VERSION "Yunle_CAN_Integrated_CANdb Release v1.0.2"

NS_ :

BS_:

BU_: ACU ADAS BMS Compressor Diagnostics ECAS EPS HVAC IBC Motor_Control SAS_SW SCU TBOX TPMS UDAN VCU Vector__XXX
VAL_TABLE_ New_Value_Table_49 ;
VAL_TABLE_ VT_OnOff 0 "Off" 1 "On" ;
VAL_TABLE_ VT_Enable 0 "Disable" 1 "Enable" ;
VAL_TABLE_ VT_Validity 0 "Invalid" 1 "Valid" ;
VAL_TABLE_ VT_Active 0 "Inactive" 1 "Active" ;
VAL_TABLE_ VT_Request2 0 "NoRequest" 1 "Request" 2 "Reserved2" 3 "Reserved3" ;
VAL_TABLE_ VT_ShiftLevel 0 "Invalid" 1 "D" 2 "N" 3 "R" ;
VAL_TABLE_ VT_DriveMode 0 "Manual" 1 "Remote" 2 "Auto" 3 "Reserved" ;
VAL_TABLE_ VT_IgnitionState 0 "Off" 1 "Acc" 2 "On" 3 "Start" ;
VAL_TABLE_ VT_Direction 0 "LeftOrNegative" 1 "RightOrPositive" ;
VAL_TABLE_ VT_WarningLevel 0 "Normal" 1 "Warning" 2 "Derating" 3 "Fault" 4 "Severe" 5 "Reserved5" 6 "Reserved6" 7 "Reserved7" ;
VAL_TABLE_ VT_TorqueOrSpeedMode 0 "TorqueMode" 1 "SpeedMode" ;

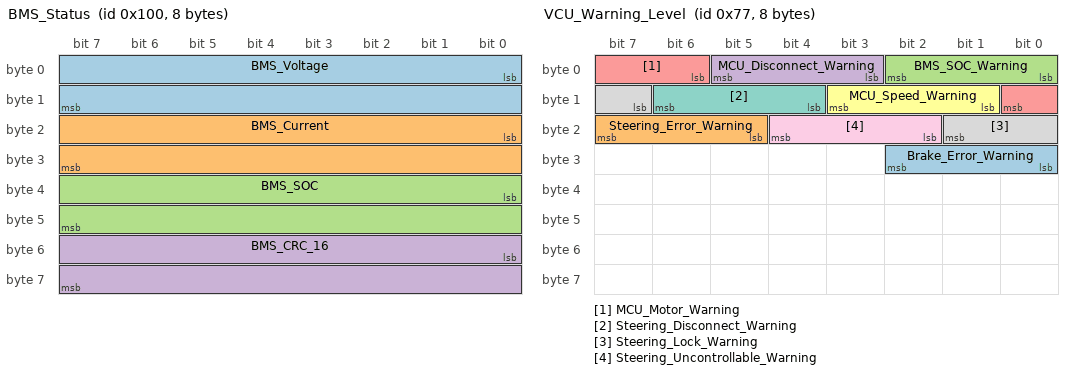
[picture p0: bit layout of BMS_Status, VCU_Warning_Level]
BO_ 256 BMS_Status: 8 BMS
 SG_ BMS_Voltage : 0|16@1+ (0.1,0) [0|100] "V"  VCU,TBOX
 SG_ BMS_Current : 16|16@1- (0.1,0) [-500|500] "A"  VCU,TBOX
 SG_ BMS_SOC : 32|16@1+ (1,0) [0|100] "%"  VCU,TBOX
 SG_ BMS_CRC_16 : 48|16@1+ (1,0) [0|65535] "" Vector__XXX

BO_ 119 VCU_Warning_Level: 8 VCU
 SG_ Brake_Error_Warning : 24|3@1+ (1,0) [0|7] "" Vector__XXX
 SG_ Steering_Error_Warning : 21|3@1+ (1,0) [0|7] "" Vector__XXX
 SG_ BMS_SOC_Warning : 0|3@1+ (1,0) [0|7] ""  SCU,TBOX
 SG_ MCU_Disconnect_Warning : 3|3@1+ (1,0) [0|7] ""  SCU,TBOX
 SG_ MCU_Motor_Warning : 6|3@1+ (1,0) [0|7] ""  SCU,TBOX
 SG_ MCU_Speed_Warning : 9|3@1+ (1,0) [0|7] ""  SCU,TBOX
 SG_ Steering_Disconnect_Warning : 12|3@1+ (1,0) [0|7] ""  SCU,TBOX
 SG_ Steering_Lock_Warning : 15|3@1+ (1,0) [0|7] ""  SCU,TBOX
 SG_ Steering_Uncontrollable_Warning : 18|3@1+ (1,0) [0|7] ""  SCU,TBOX

BO_ 1808 VCU_Debug_Enable: 8 VCU
 SG_ PID_Debug_Enable : 2|1@1+ (1,0) [0|1] ""  Diagnostics

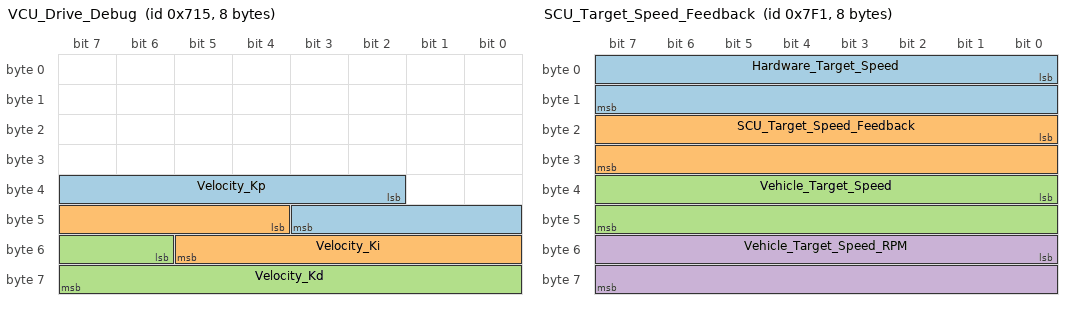
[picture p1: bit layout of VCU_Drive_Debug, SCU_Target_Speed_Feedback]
BO_ 1813 VCU_Drive_Debug: 8 VCU
 SG_ Velocity_Kp : 34|10@1+ (0.1,0) [0|102.3] ""  Diagnostics
 SG_ Velocity_Ki : 44|10@1+ (0.01,0) [0|10.23] ""  Diagnostics
 SG_ Velocity_Kd : 54|10@1+ (0.01,0) [0|10.23] ""  Diagnostics

BO_ 2033 SCU_Target_Speed_Feedback: 8 SCU
 SG_ Hardware_Target_Speed : 0|16@1- (0.1,0) [-3276.8|3276.7] "km/h"  VCU,TBOX
 SG_ SCU_Target_Speed_Feedback : 16|16@1- (0.1,0) [-3276.8|3276.7] "km/h"  VCU,TBOX
 SG_ Vehicle_Target_Speed : 32|16@1- (0.1,0) [-3276.8|3276.7] "km/h"  VCU,TBOX
 SG_ Vehicle_Target_Speed_RPM : 48|16@1- (0.1,0) [-3276.8|3276.7] "rpm"  VCU,TBOX

BO_ 225 SAS_Angle_Feedback: 8 SAS_SW
 SG_ SAS_Front_Angle : 0|16@1- (0.1,0) [-3276.8|3276.7] "deg"  VCU,TBOX
 SG_ SAS_Rear_Angle : 24|16@1- (0.1,0) [-3276.8|3276.7] "deg"  VCU,TBOX

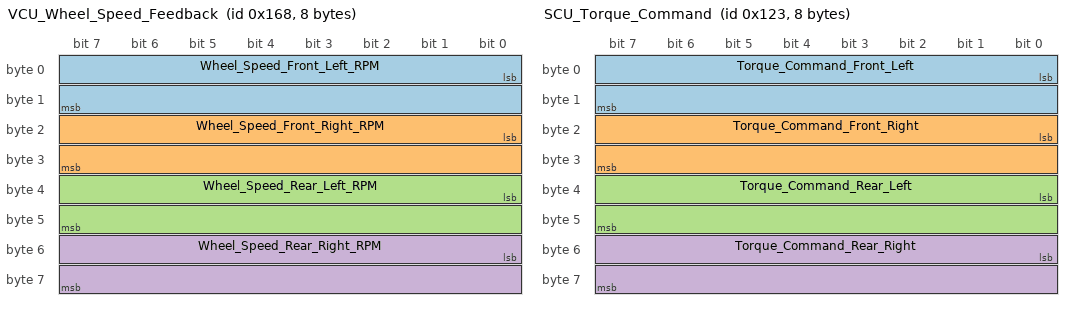
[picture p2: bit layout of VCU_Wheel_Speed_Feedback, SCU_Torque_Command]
BO_ 360 VCU_Wheel_Speed_Feedback: 8 VCU
 SG_ Wheel_Speed_Front_Left_RPM : 0|16@1- (0.1,0) [-3276.8|3276.7] "rpm"  SCU,TBOX
 SG_ Wheel_Speed_Front_Right_RPM : 16|16@1- (0.1,0) [-3276.8|3276.7] "rpm"  SCU,TBOX
 SG_ Wheel_Speed_Rear_Left_RPM : 32|16@1- (0.1,0) [-3276.8|3276.7] "rpm"  SCU,TBOX
 SG_ Wheel_Speed_Rear_Right_RPM : 48|16@1- (0.1,0) [-3276.8|3276.7] "rpm"  SCU,TBOX

BO_ 81 VCU_CCU_Status: 8 VCU
 SG_ Handle_Mode_Flag_Status : 37|1@1+ (1,0) [0|1] "" Vector__XXX
 SG_ Handle_Brake_Request_Status : 36|1@1+ (1,0) [0|1] "" Vector__XXX
 SG_ Touch_Brake_Request_Status : 35|1@1+ (1,0) [0|1] "" Vector__XXX
 SG_ CCU_Shift_Level_Status : 0|2@1+ (1,0) [0|3] ""  SCU,TBOX
 SG_ CCU_Parking_Status : 2|1@1+ (1,0) [0|1] ""  SCU,TBOX
 SG_ CCU_Ignition_Status : 3|2@1+ (1,0) [0|3] ""  SCU,TBOX
 SG_ CCU_Drive_Mode_Shift_Button : 5|1@1+ (1,0) [0|1] ""  SCU,TBOX
 SG_ Steering_Wheel_Direction : 7|1@1+ (1,0) [0|1] ""  SCU,TBOX
 SG_ CCU_Steering_Wheel_Angle : 8|12@1+ (0.1,0) [0|120] ""  SCU,TBOX
 SG_ CCU_Vehicle_Speed : 20|9@1+ (0.1,0) [0|51.1] "km/h"  SCU,TBOX
 SG_ CCU_Drive_Mode : 29|3@1+ (1,0) [0|3] ""  SCU,TBOX
 SG_ Remote_Brake_Request_Status : 32|1@1+ (1,0) [0|1] ""  SCU,TBOX
 SG_ Emergency_Brake_Request_Status : 33|1@1+ (1,0) [0|1] ""  SCU,TBOX
 SG_ SCU_Brake_Signal_Status : 34|1@1+ (1,0) [0|1] ""  SCU,TBOX
 SG_ Left_Turn_Light_Status : 56|1@1+ (1,0) [0|1] ""  SCU,TBOX
 SG_ Right_Turn_Light_Status : 57|1@1+ (1,0) [0|1] ""  SCU,TBOX
 SG_ Position_Light_Status : 59|1@1+ (1,0) [0|1] ""  SCU,TBOX
 SG_ Low_Beam_Status : 60|1@1+ (1,0) [0|1] ""  SCU,TBOX

BO_ 291 SCU_Torque_Command: 8 SCU
 SG_ Torque_Command_Front_Left : 0|16@1- (0.1,0) [-3276.8|3276.7] "Nm"  Motor_Control
 SG_ Torque_Command_Front_Right : 16|16@1- (0.1,0) [-3276.8|3276.7] "Nm"  Motor_Control
 SG_ Torque_Command_Rear_Left : 32|16@1- (0.1,0) [-3276.8|3276.7] "Nm"  Motor_Control
 SG_ Torque_Command_Rear_Right : 48|16@1- (0.1,0) [-3276.8|3276.7] "Nm"  Motor_Control

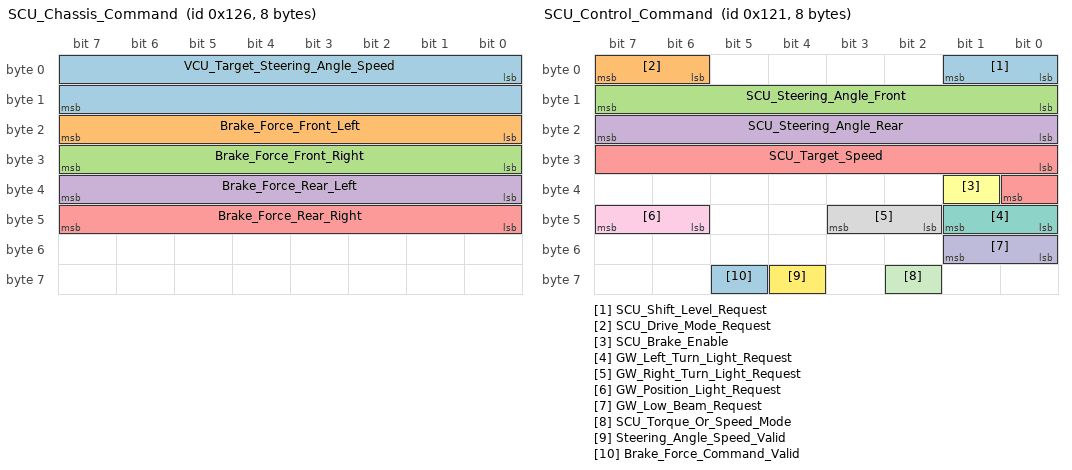
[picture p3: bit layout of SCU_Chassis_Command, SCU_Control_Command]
BO_ 294 SCU_Chassis_Command: 8 SCU
 SG_ VCU_Target_Steering_Angle_Speed : 0|16@1- (1,0) [126|525] "deg/s"  EPS,SAS_SW
 SG_ Brake_Force_Front_Left : 16|8@1+ (1,0) [0|100] "%"  ECAS
 SG_ Brake_Force_Front_Right : 24|8@1+ (1,0) [0|100] "%"  ECAS
 SG_ Brake_Force_Rear_Left : 32|8@1+ (1,0) [0|100] "%"  ECAS
 SG_ Brake_Force_Rear_Right : 40|8@1+ (1,0) [0|100] "%"  ECAS

BO_ 289 SCU_Control_Command: 8 SCU
 SG_ SCU_Shift_Level_Request : 0|2@1+ (1,0) [0|3] ""  VCU
 SG_ SCU_Drive_Mode_Request : 6|2@1+ (1,0) [0|3] ""  VCU
 SG_ SCU_Steering_Angle_Front : 8|8@1+ (1,0) [0|255] ""  VCU
 SG_ SCU_Steering_Angle_Rear : 16|8@1+ (1,0) [0|255] ""  VCU
 SG_ SCU_Target_Speed : 24|9@1+ (0.1,0) [0|51.1] "km/h"  VCU
 SG_ SCU_Brake_Enable : 33|1@1+ (1,0) [0|1] ""  VCU
 SG_ GW_Left_Turn_Light_Request : 40|2@1+ (1,0) [0|3] ""  TBOX
 SG_ GW_Right_Turn_Light_Request : 42|2@1+ (1,0) [0|3] ""  TBOX
 SG_ GW_Position_Light_Request : 46|2@1+ (1,0) [0|3] ""  TBOX
 SG_ GW_Low_Beam_Request : 48|2@1+ (1,0) [0|3] ""  TBOX
 SG_ SCU_Torque_Or_Speed_Mode : 58|1@1+ (1,0) [0|1] ""  VCU
 SG_ Steering_Angle_Speed_Valid : 60|1@1+ (1,0) [0|1] ""  VCU
 SG_ Brake_Force_Command_Valid : 61|1@1+ (1,0) [0|1] ""  VCU

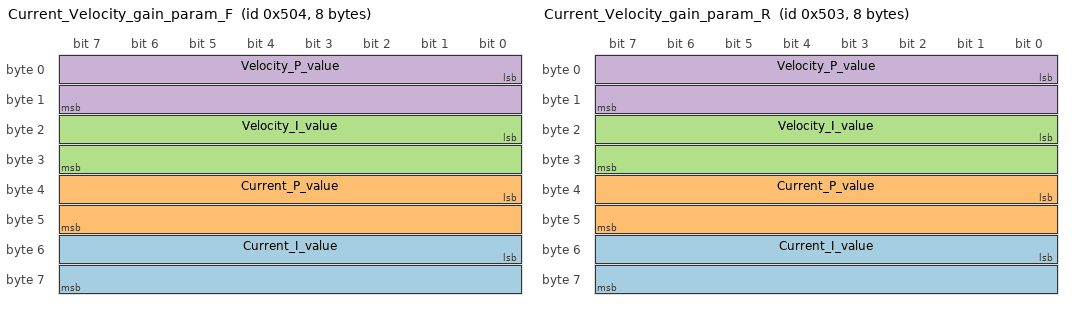
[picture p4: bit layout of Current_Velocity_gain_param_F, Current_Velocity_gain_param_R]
BO_ 1284 Current_Velocity_gain_param_F: 8 Vector__XXX
 SG_ Current_I_value : 48|16@1+ (1,0) [0|0] "" Vector__XXX
 SG_ Current_P_value : 32|16@1+ (1,0) [0|0] "" Vector__XXX
 SG_ Velocity_I_value : 16|16@1+ (1,0) [0|0] "" Vector__XXX
 SG_ Velocity_P_value : 0|16@1+ (1,0) [0|0] "" Vector__XXX

BO_ 1283 Current_Velocity_gain_param_R: 8 Vector__XXX
 SG_ Current_I_value : 48|16@1+ (1,0) [0|0] "" Vector__XXX
 SG_ Current_P_value : 32|16@1+ (1,0) [0|0] "" Vector__XXX
 SG_ Velocity_I_value : 16|16@1+ (1,0) [0|0] "" Vector__XXX
 SG_ Velocity_P_value : 0|16@1+ (1,0) [0|0] "" Vector__XXX

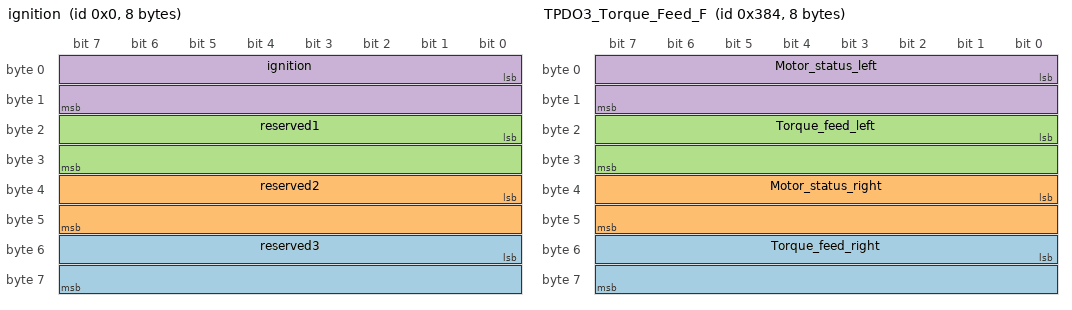
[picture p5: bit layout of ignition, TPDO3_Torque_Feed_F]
BO_ 0 ignition: 8 Vector__XXX
 SG_ reserved3 : 48|16@1+ (1,0) [0|0] "" Vector__XXX
 SG_ reserved2 : 32|16@1+ (1,0) [0|0] "" Vector__XXX
 SG_ reserved1 : 16|16@1+ (1,0) [0|0] "" Vector__XXX
 SG_ ignition : 0|16@1+ (1,0) [0|0] "" Vector__XXX

BO_ 1796 Heartbeat_F: 1 Vector__XXX
 SG_ heartbeat : 0|8@1+ (1,0) [0|0] "" Vector__XXX

BO_ 1795 Heartbeat_R: 1 Vector__XXX
 SG_ heartbeat : 0|8@1+ (1,0) [0|0] "" Vector__XXX

BO_ 1156 TPDO4_Position_Feed_F: 8 Vector__XXX
 SG_ Position_value_right : 32|32@1- (1,0) [0|0] "" Vector__XXX
 SG_ Position_value_left : 0|32@1- (1,0) [0|0] "" Vector__XXX

BO_ 1155 TPDO4_Position_Feed_R: 8 Vector__XXX
 SG_ Position_value_right : 32|32@1- (1,0) [0|0] "" Vector__XXX
 SG_ Position_value_left : 0|32@1- (1,0) [0|0] "" Vector__XXX

BO_ 900 TPDO3_Torque_Feed_F: 8 Vector__XXX
 SG_ Torque_feed_right : 48|16@1- (0.1,0) [0|0] "" Vector__XXX
 SG_ Motor_status_right : 32|16@1+ (1,0) [0|0] "" Vector__XXX
 SG_ Torque_feed_left : 16|16@1- (0.1,0) [0|0] "" Vector__XXX
 SG_ Motor_status_left : 0|16@1+ (1,0) [0|0] "" Vector__XXX

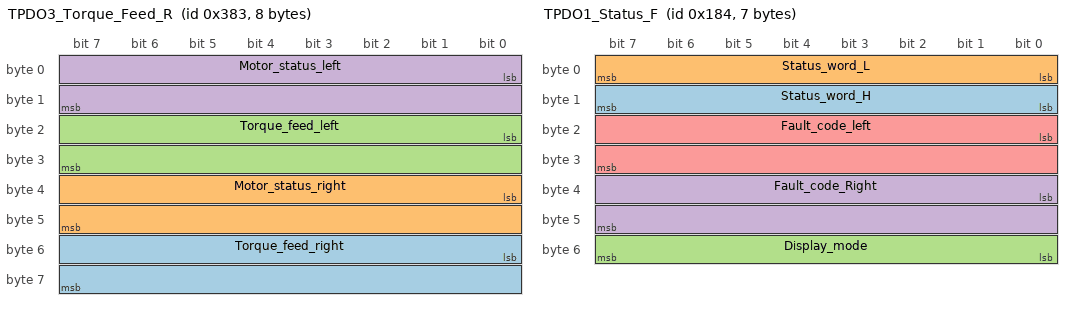
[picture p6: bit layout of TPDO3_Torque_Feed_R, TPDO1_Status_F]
BO_ 899 TPDO3_Torque_Feed_R: 8 Vector__XXX
 SG_ Torque_feed_right : 48|16@1- (0.1,0) [0|0] "" Vector__XXX
 SG_ Motor_status_right : 32|16@1+ (1,0) [0|0] "" Vector__XXX
 SG_ Torque_feed_left : 16|16@1- (0.1,0) [0|0] "" Vector__XXX
 SG_ Motor_status_left : 0|16@1+ (1,0) [0|0] "" Vector__XXX

BO_ 644 TPDO2_Speed_Feed_F: 8 Vector__XXX
 SG_ Speed_feed_right : 32|32@1- (1,0) [0|0] "" Vector__XXX
 SG_ Speed_feed_left : 0|32@1- (1,0) [0|0] "" Vector__XXX

BO_ 643 TPDO2_Speed_Feed_R: 8 Vector__XXX
 SG_ Speed_feed_right : 32|32@1- (1,0) [0|0] "" Vector__XXX
 SG_ Speed_feed_left : 0|32@1- (1,0) [0|0] "" Vector__XXX

BO_ 388 TPDO1_Status_F: 7 Vector__XXX
 SG_ Status_word_H : 8|8@1+ (1,0) [0|0] "" Vector__XXX
 SG_ Status_word_L : 0|8@1+ (1,0) [0|0] "" Vector__XXX
 SG_ Display_mode : 48|8@1+ (1,0) [0|0] "" Vector__XXX
 SG_ Fault_code_Right : 32|16@1+ (1,0) [0|0] "" Vector__XXX
 SG_ Fault_code_left : 16|16@1+ (1,0) [0|0] "" Vector__XXX

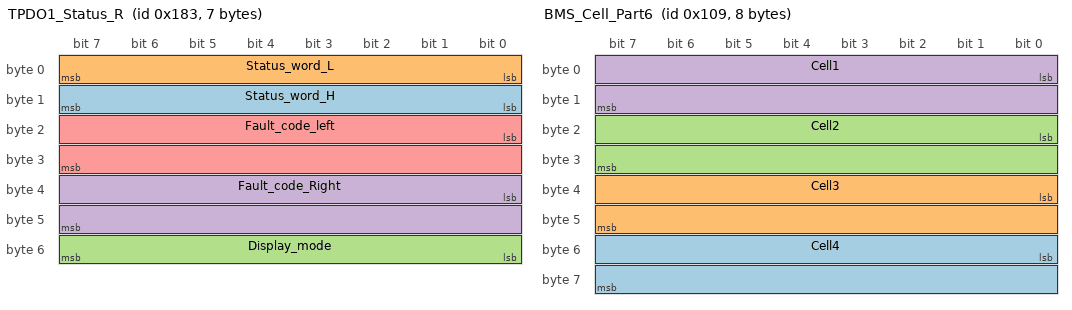
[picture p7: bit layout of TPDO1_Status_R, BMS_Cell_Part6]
BO_ 387 TPDO1_Status_R: 7 Vector__XXX
 SG_ Status_word_H : 8|8@1+ (1,0) [0|0] "" Vector__XXX
 SG_ Status_word_L : 0|8@1+ (1,0) [0|0] "" Vector__XXX
 SG_ Display_mode : 48|8@1+ (1,0) [0|0] "" Vector__XXX
 SG_ Fault_code_Right : 32|16@1+ (1,0) [0|0] "" Vector__XXX
 SG_ Fault_code_left : 16|16@1+ (1,0) [0|0] "" Vector__XXX

BO_ 1027 RPDO4_Control_R: 3 Vector__XXX
 SG_ Operation_mode_req : 16|8@1+ (1,0) [0|0] "" Vector__XXX
 SG_ control_word : 0|16@1+ (1,0) [0|0] "" Vector__XXX

BO_ 1028 RPDO4_Control_F: 3 Vector__XXX
 SG_ Operation_mode_req : 16|8@1+ (1,0) [0|0] "" Vector__XXX
 SG_ control_word : 0|16@1+ (1,0) [0|0] "" Vector__XXX

BO_ 771 RPDO2_Speed_Cmd_R: 8 Vector__XXX
 SG_ Speed_req_right : 32|32@1- (1,0) [0|0] "" Vector__XXX
 SG_ Speed_req_left : 0|32@1- (1,0) [0|0] "" Vector__XXX

BO_ 772 RPDO2_Speed_Cmd_F: 8 Vector__XXX
 SG_ Speed_req_right : 32|32@1- (1,0) [0|0] "" Vector__XXX
 SG_ Speed_req_left : 0|32@1- (1,0) [0|0] "" Vector__XXX

BO_ 516 RPDO1_Torque_Cmd_F: 4 Vector__XXX
 SG_ Torque_req_right : 16|16@1- (0.1,0) [0|0] "" Vector__XXX
 SG_ Torque_req_left : 0|16@1- (0.1,0) [0|0] "" Vector__XXX

BO_ 515 RPDO1_Torque_Cmd_R: 4 Vector__XXX
 SG_ Torque_req_right : 16|16@1- (0.1,0) [0|0] "" Vector__XXX
 SG_ Torque_req_left : 0|16@1- (0.1,0) [0|0] "" Vector__XXX

BO_ 265 BMS_Cell_Part6: 8 Vector__XXX
 SG_ Cell4 : 48|16@1+ (0.001,0) [0|0] "V" Vector__XXX
 SG_ Cell3 : 32|16@1+ (0.001,0) [0|0] "V" Vector__XXX
 SG_ Cell2 : 16|16@1+ (0.001,0) [0|0] "V" Vector__XXX
 SG_ Cell1 : 0|16@1+ (0.001,0) [0|0] "V" Vector__XXX

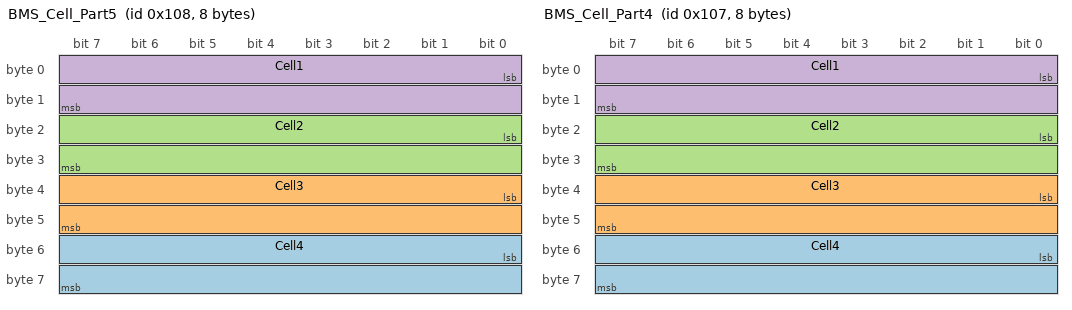
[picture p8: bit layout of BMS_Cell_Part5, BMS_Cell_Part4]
BO_ 264 BMS_Cell_Part5: 8 Vector__XXX
 SG_ Cell4 : 48|16@1+ (0.001,0) [0|0] "V" Vector__XXX
 SG_ Cell3 : 32|16@1+ (0.001,0) [0|0] "V" Vector__XXX
 SG_ Cell2 : 16|16@1+ (0.001,0) [0|0] "V" Vector__XXX
 SG_ Cell1 : 0|16@1+ (0.001,0) [0|0] "V" Vector__XXX

BO_ 263 BMS_Cell_Part4: 8 Vector__XXX
 SG_ Cell4 : 48|16@1+ (0.001,0) [0|0] "V" Vector__XXX
 SG_ Cell3 : 32|16@1+ (0.001,0) [0|0] "V" Vector__XXX
 SG_ Cell2 : 16|16@1+ (0.001,0) [0|0] "V" Vector__XXX
 SG_ Cell1 : 0|16@1+ (0.001,0) [0|0] "V" Vector__XXX

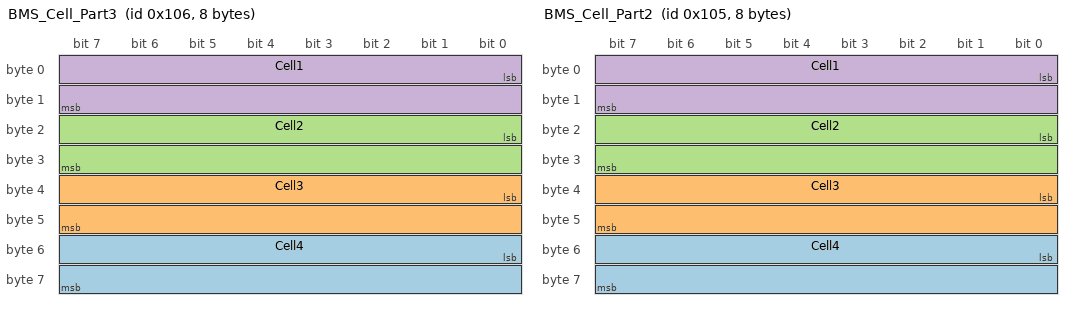
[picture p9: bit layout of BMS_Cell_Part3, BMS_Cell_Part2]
BO_ 262 BMS_Cell_Part3: 8 Vector__XXX
 SG_ Cell4 : 48|16@1+ (0.001,0) [0|0] "V" Vector__XXX
 SG_ Cell3 : 32|16@1+ (0.001,0) [0|0] "V" Vector__XXX
 SG_ Cell2 : 16|16@1+ (0.001,0) [0|0] "V" Vector__XXX
 SG_ Cell1 : 0|16@1+ (0.001,0) [0|0] "V" Vector__XXX

BO_ 261 BMS_Cell_Part2: 8 Vector__XXX
 SG_ Cell4 : 48|16@1+ (0.001,0) [0|0] "V" Vector__XXX
 SG_ Cell3 : 32|16@1+ (0.001,0) [0|0] "V" Vector__XXX
 SG_ Cell2 : 16|16@1+ (0.001,0) [0|0] "V" Vector__XXX
 SG_ Cell1 : 0|16@1+ (0.001,0) [0|0] "V" Vector__XXX

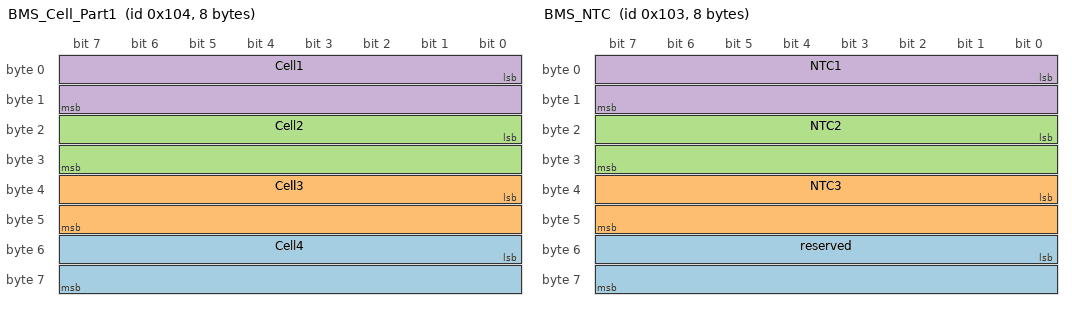
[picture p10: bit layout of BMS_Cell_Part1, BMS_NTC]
BO_ 260 BMS_Cell_Part1: 8 Vector__XXX
 SG_ Cell4 : 48|16@1+ (0.001,0) [0|0] "V" Vector__XXX
 SG_ Cell3 : 32|16@1+ (0.001,0) [0|0] "V" Vector__XXX
 SG_ Cell2 : 16|16@1+ (0.001,0) [0|0] "V" Vector__XXX
 SG_ Cell1 : 0|16@1+ (0.001,0) [0|0] "V" Vector__XXX

BO_ 259 BMS_NTC: 8 Vector__XXX
 SG_ reserved : 48|16@1- (1,0) [-32768|32767] "" Vector__XXX
 SG_ NTC3 : 32|16@1- (0.1,-273.1) [-3276.8|3276.7] "" Vector__XXX
 SG_ NTC2 : 16|16@1- (0.1,-273.1) [-3276.8|3276.7] "" Vector__XXX
 SG_ NTC1 : 0|16@1- (0.1,-273.1) [-3276.8|3276.7] "" Vector__XXX

BO_ 258 BMS_Protect_Status: 8 Vector__XXX
 SG_ CRC_16 : 48|16@1- (1,0) [0|0] "" Vector__XXX
 SG_ reserve : 45|3@1- (1,0) [0|3] "" Vector__XXX
 SG_ Lock_MOS : 44|1@1- (1,0) [0|1] "" Vector__XXX
 SG_ IC_Error : 43|1@1- (1,0) [0|1] "" Vector__XXX
 SG_ short_circuit : 42|1@1- (1,0) [0|1] "" Vector__XXX
 SG_ discharge_overCur : 41|1@1- (1,0) [0|1] "" Vector__XXX
 SG_ charge_overCur : 40|1@1- (1,0) [0|1] "" Vector__XXX
 SG_ charge_underTem : 37|1@1- (1,0) [0|1] "" Vector__XXX
 SG_ charge_overTem : 36|1@1- (1,0) [0|1] "" Vector__XXX
 SG_ discharge_unnderTem : 39|1@1- (1,0) [0|1] "" Vector__XXX
 SG_ discharge_overTem : 38|1@1- (1,0) [0|1] "" Vector__XXX
 SG_ total_undervol_protection : 35|1@1- (1,0) [0|1] "" Vector__XXX
 SG_ total_overvol_protection : 34|1@1- (1,0) [0|1] "" Vector__XXX
 SG_ single_undervol_protection : 33|1@1- (1,0) [0|1] "" Vector__XXX
 SG_ single_overvol_protection : 32|1@1- (1,0) [0|1] "" Vector__XXX
 SG_ Balance_symbol_cell33 : 16|16@1- (1,0) [0|1] "" Vector__XXX
 SG_ Balance_symbol_cell16 : 0|16@1- (1,0) [0|1] "" Vector__XXX

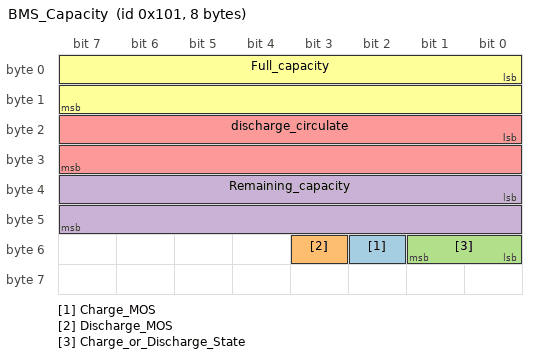
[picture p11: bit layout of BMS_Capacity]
BO_ 257 BMS_Capacity: 8 Vector__XXX
 SG_ Charge_MOS : 50|1@1- (1,0) [0|1] "" Vector__XXX
 SG_ Discharge_MOS : 51|1@1- (1,0) [0|1] "" Vector__XXX
 SG_ Charge_or_Discharge_State : 48|2@1+ (1,0) [0|0] "" Vector__XXX
 SG_ Remaining_capacity : 32|16@1+ (0.01,0) [0|10000] "Ah" Vector__XXX
 SG_ discharge_circulate : 16|16@1+ (1,0) [0|10000] "1" Vector__XXX
 SG_ Full_capacity : 0|16@1+ (0.01,0) [0|10000] "Ah" Vector__XXX

CM_ BU_ BMS "Battery Management System.";
CM_ BU_ Diagnostics "Diagnostic and calibration interface.";
CM_ BU_ ECAS "Brake or chassis actuator controller receiving force requests.";
CM_ BU_ EPS "Electric power steering controller.";
CM_ BU_ Motor_Control "Traction inverter or motor controller.";
CM_ BU_ SAS_SW "Steering angle sensor node.";
CM_ BU_ SCU "Supervisory Control Unit.";
CM_ BU_ TBOX "Telematics box.";
CM_ BU_ VCU "Vehicle Control Unit.";
CM_ BO_ 256 "Battery status message published by the BMS.";
CM_ SG_ 256 BMS_SOC "Battery state of charge. Recommended operational range: 0 to 100 %.";
CM_ BO_ 119 "Aggregated warning severity levels generated by the VCU.";
CM_ SG_ 119 Brake_Error_Warning "Warning severity for steering uncontrollable condition.";
CM_ SG_ 119 Steering_Error_Warning "Warning severity for steering uncontrollable condition.";
CM_ SG_ 119 BMS_SOC_Warning "Warning severity for BMS state of charge.";
CM_ SG_ 119 MCU_Disconnect_Warning "Warning severity for MCU communication or disconnect status.";
CM_ SG_ 119 MCU_Motor_Warning "Warning severity for motor-related faults.";
CM_ SG_ 119 MCU_Speed_Warning "Warning severity for motor speed.";
CM_ SG_ 119 Steering_Disconnect_Warning "Warning severity for steering disconnect condition.";
CM_ SG_ 119 Steering_Lock_Warning "Warning severity for steering lock condition.";
CM_ SG_ 119 Steering_Uncontrollable_Warning "Warning severity for steering uncontrollable condition.";
CM_ BO_ 1808 "Debug enable command used for diagnostic calibration workflows.";
CM_ SG_ 1808 PID_Debug_Enable "Enable flag for PID debug mode.";
CM_ BO_ 1813 "Debug parameters for longitudinal speed-loop tuning.";
CM_ SG_ 1813 Velocity_Kp "Proportional gain for velocity control loop.";
CM_ SG_ 1813 Velocity_Ki "Integral gain for velocity control loop.";
CM_ SG_ 1813 Velocity_Kd "Derivative gain for velocity control loop.";
CM_ BO_ 2033 "Target speed feedback information produced by the SCU.";
CM_ SG_ 2033 Hardware_Target_Speed "Target speed requested by hardware layer.";
CM_ SG_ 2033 SCU_Target_Speed_Feedback "Target speed feedback generated by the SCU.";
CM_ SG_ 2033 Vehicle_Target_Speed "Vehicle target speed used by the control stack.";
CM_ SG_ 2033 Vehicle_Target_Speed_RPM "Equivalent target rotational speed.";
CM_ BO_ 225 "Steering angle feedback from the steering angle sensor.";
CM_ SG_ 225 SAS_Front_Angle "Front steering angle reported by SAS.";
CM_ SG_ 225 SAS_Rear_Angle "Rear steering angle reported by SAS.";
CM_ BO_ 360 "Wheel speed feedback published by the VCU.";
CM_ SG_ 360 Wheel_Speed_Front_Left_RPM "Front-left wheel speed.";
CM_ SG_ 360 Wheel_Speed_Front_Right_RPM "Front-right wheel speed.";
CM_ SG_ 360 Wheel_Speed_Rear_Left_RPM "Rear-left wheel speed.";
CM_ SG_ 360 Wheel_Speed_Rear_Right_RPM "Rear-right wheel speed.";
CM_ BO_ 81 "CCU-related chassis and lighting status consolidated by the VCU.";
CM_ SG_ 81 Handle_Brake_Request_Status "Handle_Brake_Request_Status.";
CM_ SG_ 81 CCU_Shift_Level_Status "Current shift level status reported by the CCU.";
CM_ SG_ 81 CCU_Parking_Status "Parking status reported by the CCU.";
CM_ SG_ 81 CCU_Ignition_Status "Ignition status reported by the CCU.";
CM_ SG_ 81 CCU_Drive_Mode_Shift_Button "Drive-mode shift button status.";
CM_ SG_ 81 Steering_Wheel_Direction "Steering direction sign flag.";
CM_ SG_ 81 CCU_Steering_Wheel_Angle "Steering wheel angle reported by the CCU.";
CM_ SG_ 81 CCU_Vehicle_Speed "Vehicle speed reported by the CCU.";
CM_ SG_ 81 CCU_Drive_Mode "Drive mode reported by the CCU.";
CM_ SG_ 81 Remote_Brake_Request_Status "Remote brake request status.";
CM_ SG_ 81 Emergency_Brake_Request_Status "Emergency brake request status.";
CM_ SG_ 81 SCU_Brake_Signal_Status "Brake signal status used by the SCU.";
CM_ SG_ 81 Left_Turn_Light_Status "Left turn lamp status.";
CM_ SG_ 81 Right_Turn_Light_Status "Right turn lamp status.";
CM_ SG_ 81 Position_Light_Status "Position lamp status.";
CM_ SG_ 81 Low_Beam_Status "Low-beam lamp status.";
CM_ BO_ 291 "Torque command issued by the SCU to the motor controller.";
CM_ SG_ 291 Torque_Command_Front_Left "Torque command for front-left wheel.";
CM_ SG_ 291 Torque_Command_Front_Right "Torque command for front-right wheel.";
CM_ SG_ 291 Torque_Command_Rear_Left "Torque command for rear-left wheel.";
CM_ SG_ 291 Torque_Command_Rear_Right "Torque command for rear-right wheel.";
CM_ BO_ 294 "Chassis command message containing steering-rate and brake-force requests.";
CM_ SG_ 294 VCU_Target_Steering_Angle_Speed "Requested steering angle rate.";
CM_ SG_ 294 Brake_Force_Front_Left "Requested brake force for front-left channel.";
CM_ SG_ 294 Brake_Force_Front_Right "Requested brake force for front-right channel.";
CM_ SG_ 294 Brake_Force_Rear_Left "Requested brake force for rear-left channel.";
CM_ SG_ 294 Brake_Force_Rear_Right "Requested brake force for rear-right channel.";
CM_ BO_ 289 "Primary SCU control command message.";
CM_ SG_ 289 SCU_Shift_Level_Request "Requested shift level sent to the SCU.";
CM_ SG_ 289 SCU_Drive_Mode_Request "Requested drive mode sent to the SCU.";
CM_ SG_ 289 SCU_Steering_Angle_Front "Front steering angle command encoded.";
CM_ SG_ 289 SCU_Steering_Angle_Rear "Rear steering angle command encoded.";
CM_ SG_ 289 SCU_Target_Speed "Vehicle target speed sent to the SCU.";
CM_ SG_ 289 SCU_Brake_Enable "Brake enable request sent to the SCU.";
CM_ SG_ 289 GW_Left_Turn_Light_Request "Gateway request for left turn lamp.";
CM_ SG_ 289 GW_Right_Turn_Light_Request "Gateway request for right turn lamp.";
CM_ SG_ 289 GW_Position_Light_Request "Gateway request for position lamp.";
CM_ SG_ 289 GW_Low_Beam_Request "Gateway request for low-beam lamp.";
CM_ SG_ 289 SCU_Torque_Or_Speed_Mode "Control mode selection for SCU torque or speed control.";
CM_ SG_ 289 Steering_Angle_Speed_Valid "Validity flag for steering-rate command.";
CM_ SG_ 289 Brake_Force_Command_Valid "Validity flag for brake-force command.";
CM_ SG_ 1284 Current_I_value "Imported source comment removed for CANdb compatibility.";
CM_ SG_ 1284 Current_P_value "Imported source comment removed for CANdb compatibility.";
CM_ SG_ 1284 Velocity_I_value "Imported source comment removed for CANdb compatibility.";
CM_ SG_ 1284 Velocity_P_value "Imported source comment removed for CANdb compatibility.";
CM_ SG_ 1283 Current_I_value "Imported source comment removed for CANdb compatibility.";
CM_ SG_ 1283 Current_P_value "Imported source comment removed for CANdb compatibility.";
CM_ SG_ 1283 Velocity_I_value "Imported source comment removed for CANdb compatibility.";
CM_ SG_ 1283 Velocity_P_value "Imported source comment removed for CANdb compatibility.";
CM_ SG_ 1796 heartbeat "Imported source comment removed for CANdb compatibility.";
CM_ SG_ 1795 heartbeat "Imported source comment removed for CANdb compatibility.";
CM_ SG_ 900 Torque_feed_right "Imported source comment removed for CANdb compatibility.";
CM_ SG_ 900 Motor_status_right "Imported source comment removed for CANdb compatibility.";
CM_ SG_ 900 Torque_feed_left "Imported source comment removed for CANdb compatibility.";
CM_ SG_ 900 Motor_status_left "Imported source comment removed for CANdb compatibility.";
CM_ SG_ 899 Torque_feed_right "Imported source comment removed for CANdb compatibility.";
CM_ SG_ 899 Motor_status_right "Imported source comment removed for CANdb compatibility.";
CM_ SG_ 899 Torque_feed_left "Imported source comment removed for CANdb compatibility.";
CM_ SG_ 899 Motor_status_left "Imported source comment removed for CANdb compatibility.";
CM_ SG_ 644 Speed_feed_right "Imported source comment removed for CANdb compatibility.";
CM_ SG_ 644 Speed_feed_left "Imported source comment removed for CANdb compatibility.";
CM_ SG_ 643 Speed_feed_right "Imported source comment removed for CANdb compatibility.";
CM_ SG_ 643 Speed_feed_left "Imported source comment removed for CANdb compatibility.";
CM_ SG_ 388 Status_word_L "Imported source comment removed for CANdb compatibility.";
CM_ SG_ 388 Display_mode "Imported source comment removed for CANdb compatibility.";
CM_ SG_ 388 Fault_code_Right "Imported source comment removed for CANdb compatibility.";
CM_ SG_ 388 Fault_code_left "Imported source comment removed for CANdb compatibility.";
CM_ SG_ 387 Status_word_L "Imported source comment removed for CANdb compatibility.";
CM_ SG_ 387 Display_mode "Imported source comment removed for CANdb compatibility.";
CM_ SG_ 387 Fault_code_Right "Imported source comment removed for CANdb compatibility.";
CM_ SG_ 387 Fault_code_left "Imported source comment removed for CANdb compatibility.";
CM_ SG_ 1027 Operation_mode_req "Imported source comment removed for CANdb compatibility.";
CM_ SG_ 1027 control_word "Imported source comment removed for CANdb compatibility.";
CM_ SG_ 1028 Operation_mode_req "Imported source comment removed for CANdb compatibility.";
CM_ SG_ 1028 control_word "Imported source comment removed for CANdb compatibility.";
CM_ SG_ 771 Speed_req_right "Imported source comment removed for CANdb compatibility.";
CM_ SG_ 771 Speed_req_left "Imported source comment removed for CANdb compatibility.";
CM_ SG_ 772 Speed_req_right "Imported source comment removed for CANdb compatibility.";
CM_ SG_ 772 Speed_req_left "Imported source comment removed for CANdb compatibility.";
CM_ SG_ 516 Torque_req_right "Imported source comment removed for CANdb compatibility.";
CM_ SG_ 516 Torque_req_left "Imported source comment removed for CANdb compatibility.";
CM_ SG_ 515 Torque_req_right "Imported source comment removed for CANdb compatibility.";
CM_ SG_ 515 Torque_req_left "Imported source comment removed for CANdb compatibility.";
CM_ SG_ 265 Cell4 "Imported source comment removed for CANdb compatibility.";
CM_ SG_ 265 Cell3 "Imported source comment removed for CANdb compatibility.";
CM_ SG_ 265 Cell2 "Imported source comment removed for CANdb compatibility.";
CM_ SG_ 265 Cell1 "Imported source comment removed for CANdb compatibility.";
CM_ SG_ 264 Cell4 "Imported source comment removed for CANdb compatibility.";
CM_ SG_ 264 Cell3 "Imported source comment removed for CANdb compatibility.";
CM_ SG_ 264 Cell2 "Imported source comment removed for CANdb compatibility.";
CM_ SG_ 264 Cell1 "Imported source comment removed for CANdb compatibility.";
CM_ SG_ 263 Cell4 "Imported source comment removed for CANdb compatibility.";
CM_ SG_ 263 Cell3 "Imported source comment removed for CANdb compatibility.";
CM_ SG_ 263 Cell2 "Imported source comment removed for CANdb compatibility.";
CM_ SG_ 263 Cell1 "Imported source comment removed for CANdb compatibility.";
CM_ SG_ 262 Cell4 "Imported source comment removed for CANdb compatibility.";
CM_ SG_ 262 Cell3 "Imported source comment removed for CANdb compatibility.";
CM_ SG_ 262 Cell2 "Imported source comment removed for CANdb compatibility.";
CM_ SG_ 262 Cell1 "Imported source comment removed for CANdb compatibility.";
CM_ SG_ 261 Cell4 "Imported source comment removed for CANdb compatibility.";
CM_ SG_ 261 Cell3 "Imported source comment removed for CANdb compatibility.";
CM_ SG_ 261 Cell2 "Imported source comment removed for CANdb compatibility.";
CM_ SG_ 261 Cell1 "Imported source comment removed for CANdb compatibility.";
CM_ SG_ 260 Cell4 "Imported source comment removed for CANdb compatibility.";
CM_ SG_ 260 Cell3 "Imported source comment removed for CANdb compatibility.";
CM_ SG_ 260 Cell2 "Imported source comment removed for CANdb compatibility.";
CM_ SG_ 260 Cell1 "Imported source comment removed for CANdb compatibility.";
CM_ SG_ 259 reserved "Imported source comment removed for CANdb compatibility.";
CM_ SG_ 259 NTC3 "Imported source comment removed for CANdb compatibility.";
CM_ SG_ 259 NTC2 "Imported source comment removed for CANdb compatibility.";
CM_ SG_ 259 NTC1 "Imported source comment removed for CANdb compatibility.";
CM_ SG_ 258 CRC_16 "Imported source comment removed for CANdb compatibility.";
CM_ SG_ 258 reserve "Imported source comment removed for CANdb compatibility.";
CM_ SG_ 258 Lock_MOS "Imported source comment removed for CANdb compatibility.";
CM_ SG_ 258 IC_Error "Imported source comment removed for CANdb compatibility.";
CM_ SG_ 258 short_circuit "Imported source comment removed for CANdb compatibility.";
CM_ SG_ 258 discharge_overCur "Imported source comment removed for CANdb compatibility.";
CM_ SG_ 258 charge_overCur "Imported source comment removed for CANdb compatibility.";
CM_ SG_ 258 charge_underTem "Imported source comment removed for CANdb compatibility.";
CM_ SG_ 258 charge_overTem "Imported source comment removed for CANdb compatibility.";
CM_ SG_ 258 discharge_unnderTem "Imported source comment removed for CANdb compatibility.";
CM_ SG_ 258 discharge_overTem "Imported source comment removed for CANdb compatibility.";
CM_ SG_ 258 total_undervol_protection "Imported source comment removed for CANdb compatibility.";
CM_ SG_ 258 total_overvol_protection "Imported source comment removed for CANdb compatibility.";
CM_ SG_ 258 single_undervol_protection "Imported source comment removed for CANdb compatibility.";
CM_ SG_ 258 single_overvol_protection "Imported source comment removed for CANdb compatibility.";
CM_ SG_ 258 Balance_symbol_cell33 "Imported source comment removed for CANdb compatibility.";
CM_ SG_ 258 Balance_symbol_cell16 "Imported source comment removed for CANdb compatibility.";
CM_ SG_ 257 Charge_MOS "Imported source comment removed for CANdb compatibility.";
CM_ SG_ 257 Discharge_MOS "Imported source comment removed for CANdb compatibility.";
CM_ SG_ 257 Charge_or_Discharge_State "Imported source comment removed for CANdb compatibility.";
CM_ SG_ 257 Remaining_capacity "Imported source comment removed for CANdb compatibility.";
CM_ SG_ 257 discharge_circulate "Imported source comment removed for CANdb compatibility.";
CM_ SG_ 257 Full_capacity "Imported source comment removed for CANdb compatibility.";
CM_ SG_ 256 BMS_CRC_16 "CRC/checksum field merged from yunle_BMS.dbc.";
BA_DEF_  "BusType" STRING ;
BA_DEF_ BO_  "VFrameFormat" ENUM  "StandardCAN","ExtendedCAN","reserved","J1939PG";
BA_DEF_ BO_  "GenMsgCycleTime" INT 0 65535;
BA_DEF_ BO_  "GenMsgSendType" ENUM  "Cyclic","IfActive","NoMsgSendType","CyclicAndSpontan","Spontan","CyclicIfActive","Triggered","CyclicTriggered","CyclicWithRepeatOnChange","IfActiveWithRepeatOnChange","IfActiveFast","CyclicIfActiveFast","NotUsed";
BA_DEF_DEF_  "BusType" "CAN";
BA_DEF_DEF_  "VFrameFormat" "StandardCAN";
BA_DEF_DEF_  "GenMsgCycleTime" 100;
BA_DEF_DEF_  "GenMsgSendType" "Cyclic";
BA_ "GenMsgCycleTime" BO_ 81 20;
BA_ "GenMsgCycleTime" BO_ 225 20;
BA_ "GenMsgCycleTime" BO_ 289 20;
BA_ "GenMsgCycleTime" BO_ 291 20;
BA_ "GenMsgCycleTime" BO_ 294 20;
BA_ "GenMsgCycleTime" BO_ 360 20;
BA_ "GenMsgCycleTime" BO_ 2033 20;
VAL_ 119 Brake_Error_Warning 4 "Severe" 3 "Fault" 2 "Derating" 1 "Warning" 0 "Normal" ;
VAL_ 119 Steering_Error_Warning 4 "Severe" 3 "Fault" 2 "Derating" 1 "Warning" 0 "Normal" ;
VAL_ 119 BMS_SOC_Warning 0 "Normal" 1 "Warning" 2 "Derating" 3 "Fault" 4 "Severe" ;
VAL_ 119 MCU_Disconnect_Warning 0 "Normal" 1 "Warning" 2 "Derating" 3 "Fault" 4 "Severe" ;
VAL_ 119 MCU_Motor_Warning 0 "Normal" 1 "Warning" 2 "Derating" 3 "Fault" 4 "Severe" ;
VAL_ 119 MCU_Speed_Warning 0 "Normal" 1 "Warning" 2 "Derating" 3 "Fault" 4 "Severe" ;
VAL_ 119 Steering_Disconnect_Warning 0 "Normal" 1 "Warning" 2 "Derating" 3 "Fault" 4 "Severe" ;
VAL_ 119 Steering_Lock_Warning 0 "Normal" 1 "Warning" 2 "Derating" 3 "Fault" 4 "Severe" ;
VAL_ 119 Steering_Uncontrollable_Warning 4 "Severe" 3 "Fault" 2 "Derating" 1 "Warning" 0 "Normal" ;
VAL_ 1808 PID_Debug_Enable 0 "Disable" 1 "Enable" ;
VAL_ 81 CCU_Shift_Level_Status 0 "Invalid" 1 "D" 2 "N" 3 "R" ;
VAL_ 81 CCU_Parking_Status 0 "Released" 1 "Applied" ;
VAL_ 81 CCU_Ignition_Status 0 "Off" 1 "Acc" 2 "On" 3 "Start" ;
VAL_ 81 CCU_Drive_Mode_Shift_Button 0 "Manual" 1 "ShiftButtonPressed" ;
VAL_ 81 Steering_Wheel_Direction 0 "LeftOrNegative" 1 "RightOrPositive" ;
VAL_ 81 Remote_Brake_Request_Status 0 "Inactive" 1 "Active" ;
VAL_ 81 SCU_Brake_Signal_Status 0 "Inactive" 1 "Active" ;
VAL_ 81 Left_Turn_Light_Status 0 "Off" 1 "On" ;
VAL_ 81 Right_Turn_Light_Status 0 "Off" 1 "On" ;
VAL_ 81 Position_Light_Status 0 "Off" 1 "On" ;
VAL_ 81 Low_Beam_Status 0 "Off" 1 "On" ;
VAL_ 289 SCU_Shift_Level_Request 0 "Invalid" 1 "D" 2 "N" 3 "R" ;
VAL_ 289 SCU_Drive_Mode_Request 0 "Manual" 1 "Remote" 2 "Auto" 3 "Reserved" ;
VAL_ 289 SCU_Brake_Enable 0 "Disable" 1 "Enable" ;
VAL_ 289 GW_Left_Turn_Light_Request 0 "NoRequest" 1 "Request" 2 "Reserved2" 3 "Reserved3" ;
VAL_ 289 GW_Right_Turn_Light_Request 0 "NoRequest" 1 "Request" 2 "Reserved2" 3 "Reserved3" ;
VAL_ 289 GW_Position_Light_Request 0 "NoRequest" 1 "Request" 2 "Reserved2" 3 "Reserved3" ;
VAL_ 289 GW_Low_Beam_Request 0 "NoRequest" 1 "Request" 2 "Reserved2" 3 "Reserved3" ;
VAL_ 289 SCU_Torque_Or_Speed_Mode 0 "TorqueMode" 1 "SpeedMode" ;
VAL_ 289 Steering_Angle_Speed_Valid 0 "Invalid" 1 "Valid" ;
VAL_ 289 Brake_Force_Command_Valid 0 "Invalid" 1 "Valid" ;
